# M367 register map
File version: 0.1
CPU: 
Registers are 32-bit, read-write, reset 0x0 unless marked. A register's access mark holds for its fields unless they carry their own. Offsets are from the block's base; [hi:lo] are bit positions; {n}, {i} and the like mark numbered series.

## RMC — Remote Control Signal Preprocessor (RMC)
Base 0x400E7000
0x00 EN — RMC Enable Register
  [0] RMCEN
0x04 REN — RMC Receive Enable Register
  [0] RMCREN
0x08 RBUF1 ro — RMC Receive Data Buffer Register 1
  [31:0] RMCRBUF
0x0C RBUF2 ro — RMC Receive Data Buffer Register 2
  [31:0] RMCRBUF
0x10 RBUF3 ro — RMC Receive Data Buffer Register 3
  [7:0] RMCRBUF
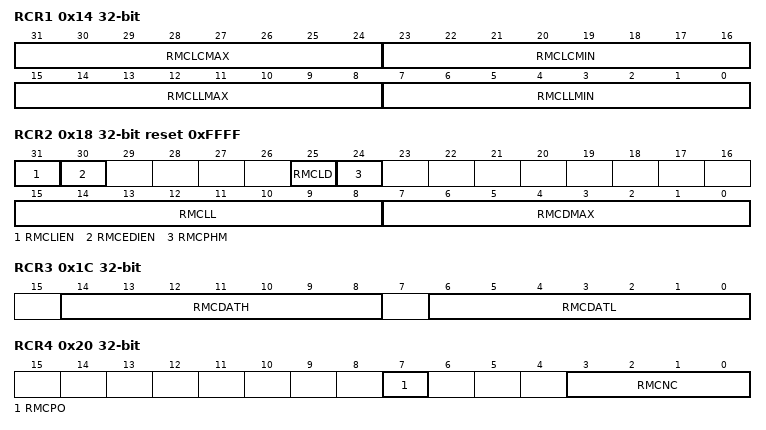
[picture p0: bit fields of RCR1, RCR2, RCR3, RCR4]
0x14 RCR1 — RMC Receive Control Register 1
  [31:24] RMCLCMAX, [23:16] RMCLCMIN, [15:8] RMCLLMAX, [7:0] RMCLLMIN
0x18 RCR2 reset 0xFFFF — RMC Receive Control Register 2
  [31] RMCLIEN, [30] RMCEDIEN, [25] RMCLD, [24] RMCPHM, [15:8] RMCLL, [7:0] RMCDMAX
0x1C RCR3 — RMC Receive Control Register 3
  [14:8] RMCDATH, [6:0] RMCDATL
0x20 RCR4 — RMC Receive Control Register 4
  [7] RMCPO, [3:0] RMCNC
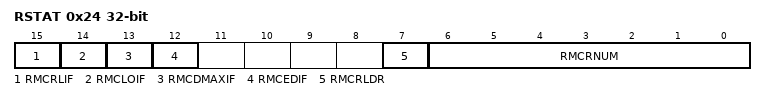
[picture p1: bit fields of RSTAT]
0x24 RSTAT ro — RMC Receive Status Register
  [15] RMCRLIF, [14] RMCLOIF, [13] RMCDMAXIF, [12] RMCEDIF, [7] RMCRLDR, [6:0] RMCRNUM
{0x24+4i} END{i} (i=1..3) — RMC Receive End Bit Number Register {i}
  [6:0] RMCEND{i}
0x34 FSSEL — RMC Frequency Selection Register
  [0] RMCCLK

## OFD — Oscillation Frequency Detector (OFD)
Base 0x400F1000
0x00 CR1 reset 0x6 — OFD Control Register 1
  [7:0] OFDWEN
0x04 CR2 — OFD Control Register 2
  [7:0] OFDEN
0x08 MN0 — OFD Lower Detection Frequency Setting Register
  [8:0] OFDMN0
0x0C MN1 — OFD Lower Detection Frequency Setting Register
  [8:0] OFDMN1
0x10 MX0 — OFD Higher Detection Frequency Setting Register
  [8:0] OFDMX0
0x14 MX1 — OFD Higher Detection Frequency Setting Register
  [8:0] OFDMX1
0x18 RST reset 0x1 — OFD Reset Enable Control Register
  [0] OFDRSTEN
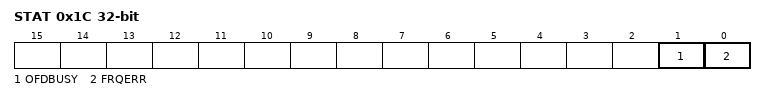
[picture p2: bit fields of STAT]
0x1C STAT ro — OFD Status Register
  [1] OFDBUSY, [0] FRQERR
0x20 MON reset 0x1 — OFD
  [0] OFDMON

## WD — Watchdog Timer (WD)
Base 0x400F2000
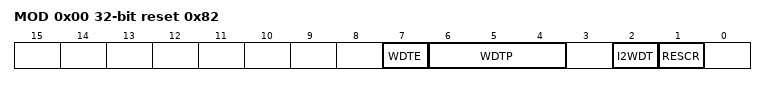
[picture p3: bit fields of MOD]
0x00 MOD reset 0x82 — WD Mode Register
  [7] WDTE, [6:4] WDTP, [2] I2WDT, [1] RESCR
0x04 CR wo (reset mask 0xFFFFFF00) — WD Control Register

## CG — Clock Generator (CG)
Base 0x400F3000
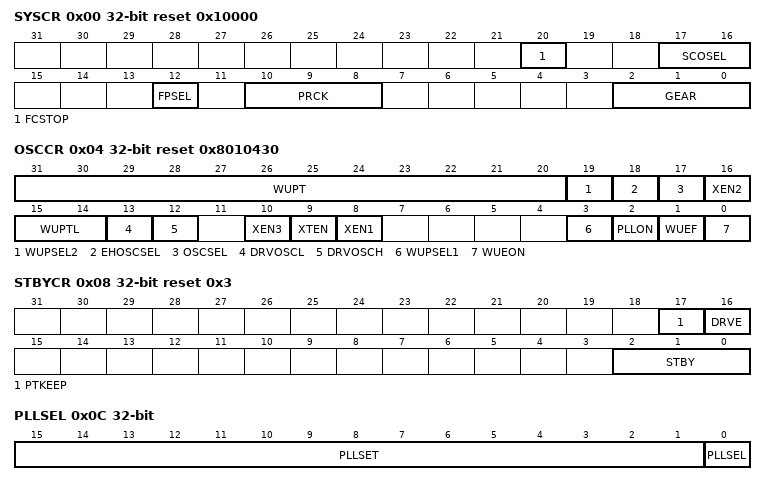
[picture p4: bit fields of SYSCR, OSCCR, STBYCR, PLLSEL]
0x00 SYSCR reset 0x10000 — System Control Register
  [20] FCSTOP, [17:16] SCOSEL, [12] FPSEL, [10:8] PRCK, [2:0] GEAR
0x04 OSCCR reset 0x8010430 — Oscillation Control Register
  [31:20] WUPT, [19] WUPSEL2, [18] EHOSCSEL, [17] OSCSEL, [16] XEN2, [15:14] WUPTL, [13] DRVOSCL, [12] DRVOSCH, [10] XEN3, [9] XTEN, [8] XEN1, [3] WUPSEL1, [2] PLLON, [1] WUEF ro, [0] WUEON wo
0x08 STBYCR reset 0x3 — Standby Control Register
  [17] PTKEEP, [16] DRVE, [2:0] STBY
0x0C PLLSEL — PLL Selection Register
  [15:1] PLLSET, [0] PLLSEL
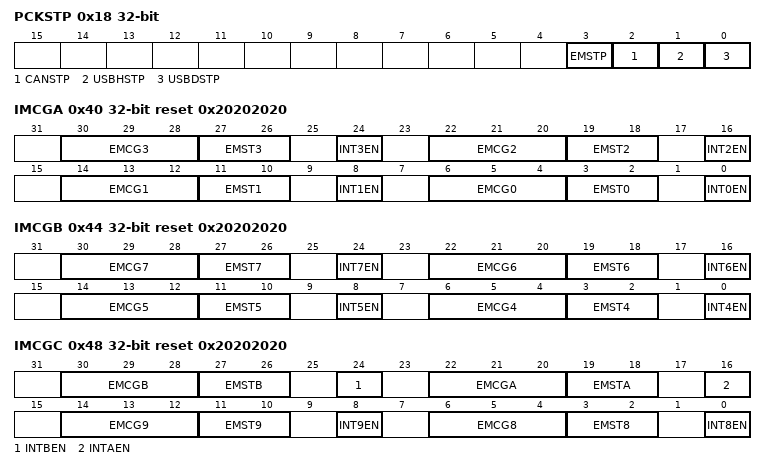
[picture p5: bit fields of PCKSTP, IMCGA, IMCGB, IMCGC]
0x18 PCKSTP — Peripheral Clock Stop Register
  [3] EMSTP, [2] CANSTP, [1] USBHSTP, [0] USBDSTP
0x3C PROTECT reset 0xC1
  [7:0] CGPROTECT
0x40 IMCGA reset 0x20202020 — CG Interrupt Mode Control Register A
  [8n+6:8n+4] EMCG{n} (n=0..3), [8n+3:8n+2] EMST{n} ro (n=0..3), [8n] INT{n}EN (n=0..3)
0x44 IMCGB reset 0x20202020 — CG Interrupt Mode Control Register B
  [8n-26:8n-28] EMCG{n} (n=4..7), [8n-29:8n-30] EMST{n} ro (n=4..7), [8n-32] INT{n}EN (n=4..7)
0x48 IMCGC reset 0x20202020 — CG Interrupt Mode Control Register C
  [30:28] EMCGB, [27:26] EMSTB ro, [24] INTBEN, [22:20] EMCGA, [19:18] EMSTA ro, [16] INTAEN, [14:12] EMCG9, [11:10] EMST9 ro, [8] INT9EN, [6:4] EMCG8, [3:2] EMST8 ro, [0] INT8EN
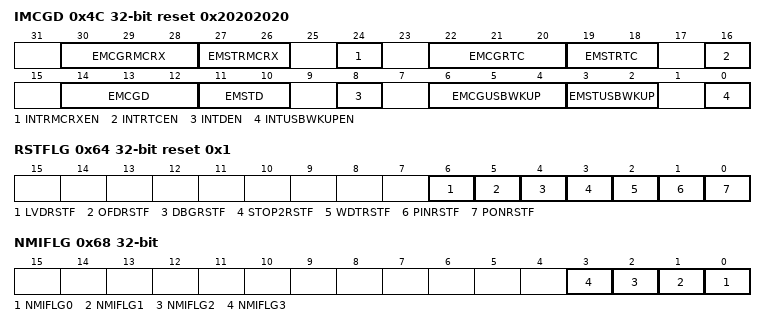
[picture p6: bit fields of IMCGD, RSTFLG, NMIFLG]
0x4C IMCGD reset 0x20202020 — CG Interrupt Mode Control Register D
  [30:28] EMCGRMCRX, [27:26] EMSTRMCRX ro, [24] INTRMCRXEN, [22:20] EMCGRTC, [19:18] EMSTRTC ro, [16] INTRTCEN, [14:12] EMCGD, [11:10] EMSTD ro, [8] INTDEN, [6:4] EMCGUSBWKUP, [3:2] EMSTUSBWKUP ro, [0] INTUSBWKUPEN
0x60 ICRCG wo — CG Interrupt Request Clear Register
  [4:0] ICRCG
0x64 RSTFLG reset 0x1 — Reset Flag Register
  [6] LVDRSTF, [5] OFDRSTF, [4] DBGRSTF, [3] STOP2RSTF, [2] WDTRSTF, [1] PINRSTF, [0] PONRSTF
0x68 NMIFLG ro — NMI Flag Register
  [n] NMIFLG{n} (n=0..3)

## USBPLL — Low Voltage detector control register
Base 0x400F3100
0x00 CR — USB PLL Control Register
  [0] USBPLLON
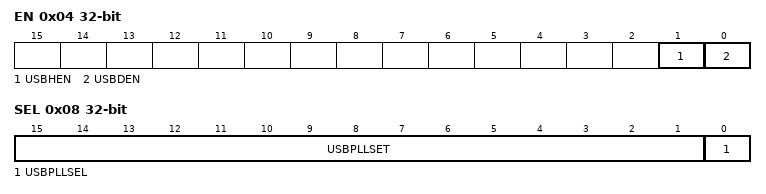
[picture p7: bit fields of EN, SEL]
0x04 EN — USB PLL Enable Register
  [1] USBHEN, [0] USBDEN
0x08 SEL — USB PLL Select Register
  [15:1] USBPLLSET, [0] USBPLLSEL

## TRMOSC — Low Voltage detector control register
Base 0x400F3200
0x00 PRO — Protection Register
  [7:0] PROTECT
0x04 EN — Enable Register
  [0] TRIMEN
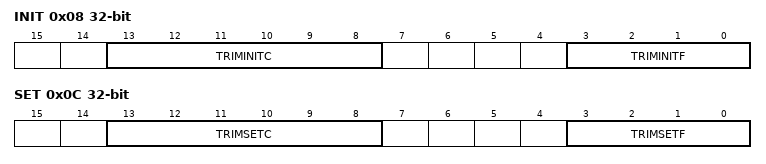
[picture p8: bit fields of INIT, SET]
0x08 INIT ro (reset mask 0xFFFFC0F0) — Initial Trimming Level Monitor Register
  [13:8] TRIMINITC, [3:0] TRIMINITF
0x0C SET — Trimming Level Setting Register
  [13:8] TRIMSETC, [3:0] TRIMSETF

## LVD — Low Voltage detector control register
Base 0x400F4000
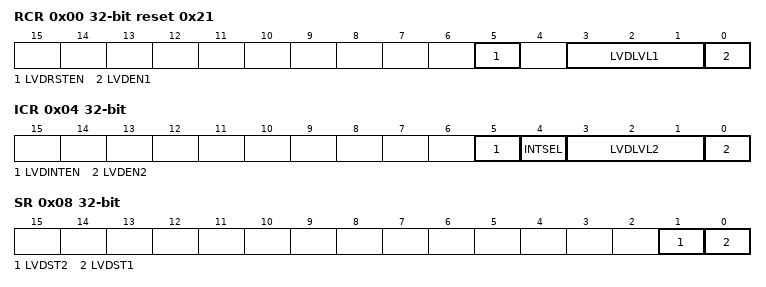
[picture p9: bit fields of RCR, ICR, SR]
0x00 RCR reset 0x21 — LVD-RESET Control Register
  [5] LVDRSTEN, [3:1] LVDLVL1, [0] LVDEN1
0x04 ICR — LVD-NMI Control Register
  [5] LVDINTEN, [4] INTSEL, [3:1] LVDLVL2, [0] LVDEN2
0x08 SR — LVD Status Control Register
  [1] LVDST2, [0] LVDST1

## MTPD — 16-bit Multi-Purpose Timer (MPT-PMD)
Base 0x400F6000
0x00 MDEN — PMD Enable Register
  [0] PWMEN
0x04 PORTMD — Port Output Mode Register
  [0] PORTMD
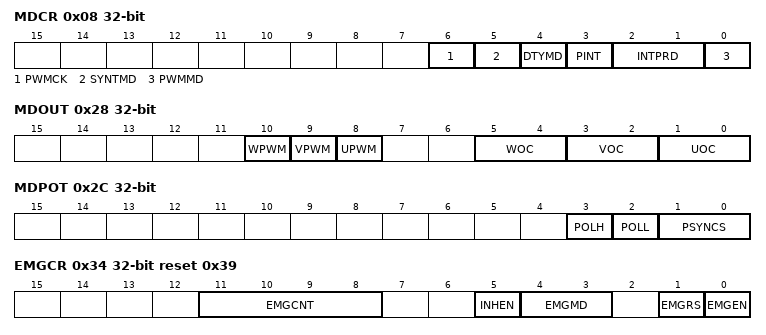
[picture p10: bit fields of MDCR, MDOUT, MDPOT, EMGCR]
0x08 MDCR — PMD Control Register
  [6] PWMCK, [5] SYNTMD, [4] DTYMD, [3] PINT, [2:1] INTPRD, [0] PWMMD
0x0C CNTSTA ro — PWM Counter Status Register
  [0] UPDWN
0x10 MDCNT ro — PWM Counter Register
  [15:0] MDCNT
0x14 MDPRD — PWM Period Register
  [15:0] MDPRD
0x18 CMPU — PWM Compare Register
  [15:0] CMPU
0x1C CMPV — PWM Compare Register
  [15:0] CMPV
0x20 CMPW — PWM Compare Register
  [15:0] CMPW
0x28 MDOUT — PMD Output Control Register
  [10] WPWM, [9] VPWM, [8] UPWM, [5:4] WOC, [3:2] VOC, [1:0] UOC
0x2C MDPOT — PMD Output Setting Register
  [3] POLH, [2] POLL, [1:0] PSYNCS
0x30 EMGREL wo — EMG Release Register
  [7:0] EMGREL
0x34 EMGCR reset 0x39 — EMG Control Register
  [11:8] EMGCNT, [5] INHEN, [4:3] EMGMD, [1] EMGRS wo, [0] EMGEN
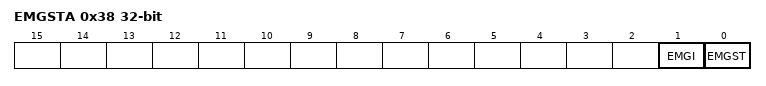
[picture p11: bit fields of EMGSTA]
0x38 EMGSTA ro (reset mask 0xFFFFFFFD) — EMG Status Register
  [1] EMGI, [0] EMGST
0x44 DTR — Dead Time Register
  [7:0] DTR

## EN — Encoder Input (ENC)
Base 0x400F7000
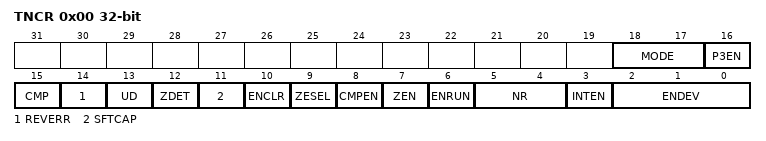
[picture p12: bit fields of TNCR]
0x00 TNCR — Encoder Input Control Register
  [18:17] MODE, [16] P3EN, [15] CMP ro, [14] REVERR ro, [13] UD ro, [12] ZDET ro, [11] SFTCAP wo, [10] ENCLR wo, [9] ZESEL, [8] CMPEN, [7] ZEN, [6] ENRUN, [5:4] NR, [3] INTEN, [2:0] ENDEV
0x04 RELOAD — Encoder Counter Reload Register
  [15:0] RELOAD
0x08 INT — Encoder Compare Register
  [23:0] INT
0x0C CNT — Encoder Counter Register
  [23:0] CNT

## FC — Flash Control (FC)
Base 0x41FFF000
0x10 SECBIT reset 0x1 — FC Security Bit Register
  [0] SECBIT
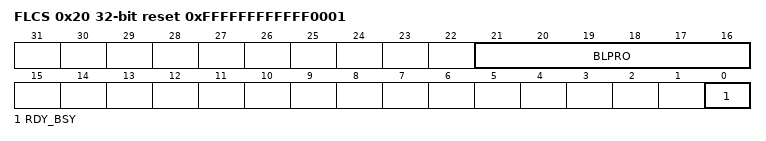
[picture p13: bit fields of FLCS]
0x20 FLCS ro reset 0xFFFFFFFFFFFF0001 — FC Flash Control Register
  [21:16] BLPRO, [0] RDY_BSY
